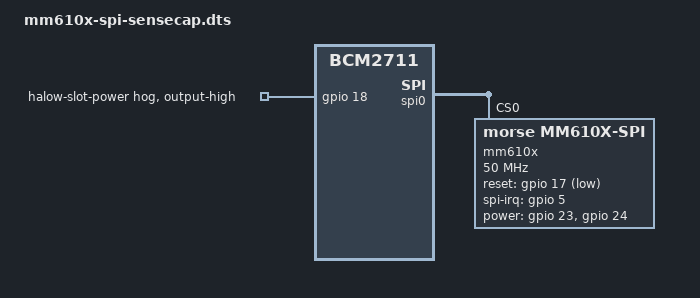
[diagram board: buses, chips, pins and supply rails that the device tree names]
/*
 * Wio-WM6108 (Morse Micro MM6108, SPI) in the SenseCAP M1 mPCIe slot.
 *
 * Pin map is the Seeed WM1302 Pi HAT one, which the M1 carrier reuses:
 *   MISO GPIO9  MOSI GPIO10  CLK GPIO11  CS GPIO8   (spi0.0)
 *   RESET_N GPIO17   SPI_INT GPIO5   WAKE GPIO23   BUSY GPIO24
 * GPIO18 is the M1's own slot power enable and is not part of the HAT map.
 *
 * RESET_N is active low. morse_hw_reset() drives it low for 20 ms and then
 * *floats* it (gpio_direction_input) rather than driving it high, relying on a
 * pull-up to release the chip. The BCM2711 defaults GPIO17 to pull-down, which
 * would hold the radio in reset forever, so GPIO17 is switched to pull-up here.
 */

/dts-v1/;
/plugin/;

/ {
	compatible = "brcm,bcm2711";

	/* Slot power enable: hog GPIO18 high for the life of the system. */
	fragment@0 {
		target = <&gpio>;
		__overlay__ {
			halow_pwr_hog {
				gpio-hog;
				gpios = <18 0>;
				output-high;
				line-name = "halow-slot-power";
			};

			halow_pins: halow_pins {
				brcm,pins = <17 5 23 24>;
				brcm,function = <0 0 0 0>;	/* all inputs */
				brcm,pull = <2 1 1 1>;		/* 17 up (reset release), rest down */
			};
		};
	};

	fragment@1 {
		target = <&spi0>;
		__overlay__ {
			status = "okay";
			#address-cells = <1>;
			#size-cells = <0>;

			mm610x@0 {
				compatible = "morse,mm610x-spi";
				reg = <0>;
				/*
				 * 50 MHz: the value every reference design uses --
				 * Morse's own EKH01 overlay in APPNOTE-24, OpenMANET,
				 * and the Heltec HT-HC01P. Measured clean on this
				 * carrier (SPI errors 0, timedout 0, no CRC/CMD53/
				 * CMD63 at any rung of a 10/20/50 MHz ladder) and
				 * worth 2.6x the throughput of the 10 MHz this file
				 * used to carry: the driver's inter-transaction delay
				 * is counted in clocks, so its 250-byte floor costs
				 * 200 us at 10 MHz and 40 us at 50.
				 *
				 * To reproduce defect 3 (patches/upstream/0003), put
				 * the clock back at load time -- the module parameter
				 * overrides this node in both directions:
				 *   modprobe morse country=SG bcf=... spi_clock_speed=10000000
				 */
				spi-max-frequency = <50000000>;
				pinctrl-names = "default";
				pinctrl-0 = <&halow_pins>;
				reset-gpios = <&gpio 17 1>;		/* active low */
				spi-irq-gpios = <&gpio 5 0>;
				power-gpios = <&gpio 23 0>, <&gpio 24 0>;	/* wake, busy */
				status = "okay";
			};
		};
	};

	/* spidev on CS0 would fight the driver for the bus. */
	fragment@2 {
		target = <&spidev0>;
		__overlay__ {
			status = "disabled";
		};
	};
};
